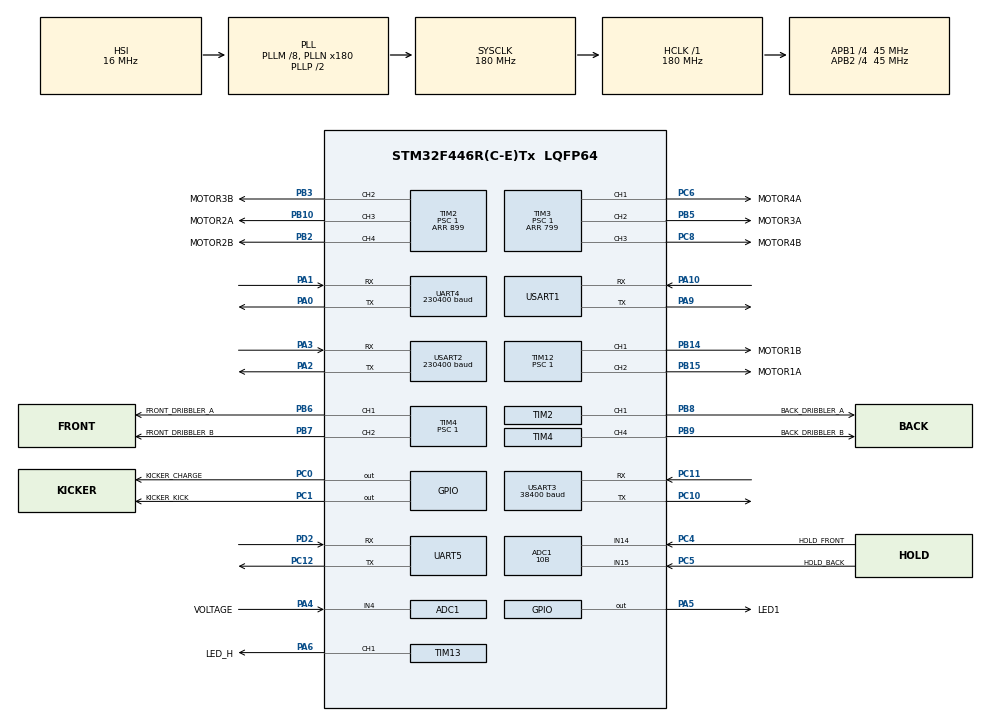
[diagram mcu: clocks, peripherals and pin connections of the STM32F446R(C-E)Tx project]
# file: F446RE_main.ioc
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ADC1.Channel-0\#ChannelRegularConversion=ADC_CHANNEL_4
ADC1.Channel-1\#ChannelRegularConversion=ADC_CHANNEL_14
ADC1.Channel-2\#ChannelRegularConversion=ADC_CHANNEL_15
ADC1.ContinuousConvMode=ENABLE
ADC1.DMAContinuousRequests=ENABLE
ADC1.NbrOfConversion=3
ADC1.NbrOfConversionFlag=1
ADC1.Rank-0\#ChannelRegularConversion=1
ADC1.Rank-1\#ChannelRegularConversion=2
ADC1.Rank-2\#ChannelRegularConversion=3
ADC1.Resolution=ADC_RESOLUTION_10B
ADC1.SamplingTime-0\#ChannelRegularConversion=ADC_SAMPLETIME_15CYCLES
ADC1.SamplingTime-1\#ChannelRegularConversion=ADC_SAMPLETIME_15CYCLES
ADC1.SamplingTime-2\#ChannelRegularConversion=ADC_SAMPLETIME_15CYCLES
ADC1.master=1
Dma.ADC1.2.Direction=DMA_PERIPH_TO_MEMORY
Dma.ADC1.2.FIFOMode=DMA_FIFOMODE_DISABLE
Dma.ADC1.2.Instance=DMA2_Stream0
Dma.ADC1.2.MemDataAlignment=DMA_MDATAALIGN_HALFWORD
Dma.ADC1.2.MemInc=DMA_MINC_ENABLE
Dma.ADC1.2.Mode=DMA_CIRCULAR
Dma.ADC1.2.PeriphDataAlignment=DMA_PDATAALIGN_HALFWORD
Dma.ADC1.2.PeriphInc=DMA_PINC_DISABLE
Dma.ADC1.2.Priority=DMA_PRIORITY_LOW
Dma.Request0=USART1_RX
Dma.Request1=USART1_TX
Dma.Request10=UART5_TX
Dma.Request2=ADC1
Dma.Request3=USART2_RX
Dma.Request4=USART2_TX
Dma.Request5=USART3_RX
Dma.Request6=USART3_TX
Dma.Request7=UART4_RX
Dma.Request8=UART4_TX
Dma.Request9=UART5_RX
Dma.UART4_RX.7.Direction=DMA_PERIPH_TO_MEMORY
Dma.UART4_RX.7.FIFOMode=DMA_FIFOMODE_DISABLE
Dma.UART4_RX.7.Instance=DMA1_Stream2
Dma.UART4_RX.7.MemDataAlignment=DMA_MDATAALIGN_BYTE
Dma.UART4_RX.7.MemInc=DMA_MINC_ENABLE
Dma.UART4_RX.7.Mode=DMA_CIRCULAR
Dma.UART4_RX.7.PeriphDataAlignment=DMA_PDATAALIGN_BYTE
Dma.UART4_RX.7.PeriphInc=DMA_PINC_DISABLE
Dma.UART4_RX.7.Priority=DMA_PRIORITY_LOW
Dma.UART4_TX.8.Direction=DMA_MEMORY_TO_PERIPH
Dma.UART4_TX.8.FIFOMode=DMA_FIFOMODE_DISABLE
Dma.UART4_TX.8.Instance=DMA1_Stream4
Dma.UART4_TX.8.MemDataAlignment=DMA_MDATAALIGN_BYTE
Dma.UART4_TX.8.MemInc=DMA_MINC_ENABLE
Dma.UART4_TX.8.Mode=DMA_CIRCULAR
Dma.UART4_TX.8.PeriphDataAlignment=DMA_PDATAALIGN_BYTE
Dma.UART4_TX.8.PeriphInc=DMA_PINC_DISABLE
Dma.UART4_TX.8.Priority=DMA_PRIORITY_LOW
Dma.UART5_RX.9.Direction=DMA_PERIPH_TO_MEMORY
Dma.UART5_RX.9.FIFOMode=DMA_FIFOMODE_DISABLE
Dma.UART5_RX.9.Instance=DMA1_Stream0
Dma.UART5_RX.9.MemDataAlignment=DMA_MDATAALIGN_BYTE
Dma.UART5_RX.9.MemInc=DMA_MINC_ENABLE
Dma.UART5_RX.9.Mode=DMA_CIRCULAR
Dma.UART5_RX.9.PeriphDataAlignment=DMA_PDATAALIGN_BYTE
Dma.UART5_RX.9.PeriphInc=DMA_PINC_DISABLE
Dma.UART5_RX.9.Priority=DMA_PRIORITY_LOW
Dma.UART5_TX.10.Direction=DMA_MEMORY_TO_PERIPH
Dma.UART5_TX.10.FIFOMode=DMA_FIFOMODE_DISABLE
Dma.UART5_TX.10.Instance=DMA1_Stream7
Dma.UART5_TX.10.MemDataAlignment=DMA_MDATAALIGN_BYTE
Dma.UART5_TX.10.MemInc=DMA_MINC_ENABLE
Dma.UART5_TX.10.Mode=DMA_CIRCULAR
Dma.UART5_TX.10.PeriphDataAlignment=DMA_PDATAALIGN_BYTE
Dma.UART5_TX.10.PeriphInc=DMA_PINC_DISABLE
Dma.UART5_TX.10.Priority=DMA_PRIORITY_LOW
Dma.USART1_RX.0.Direction=DMA_PERIPH_TO_MEMORY
Dma.USART1_RX.0.FIFOMode=DMA_FIFOMODE_DISABLE
Dma.USART1_RX.0.Instance=DMA2_Stream2
Dma.USART1_RX.0.MemDataAlignment=DMA_MDATAALIGN_BYTE
Dma.USART1_RX.0.MemInc=DMA_MINC_ENABLE
Dma.USART1_RX.0.Mode=DMA_CIRCULAR
Dma.USART1_RX.0.PeriphDataAlignment=DMA_PDATAALIGN_BYTE
Dma.USART1_RX.0.PeriphInc=DMA_PINC_DISABLE
Dma.USART1_RX.0.Priority=DMA_PRIORITY_LOW
Dma.USART1_TX.1.Direction=DMA_MEMORY_TO_PERIPH
Dma.USART1_TX.1.FIFOMode=DMA_FIFOMODE_DISABLE
Dma.USART1_TX.1.Instance=DMA2_Stream7
Dma.USART1_TX.1.MemDataAlignment=DMA_MDATAALIGN_BYTE
Dma.USART1_TX.1.MemInc=DMA_MINC_ENABLE
Dma.USART1_TX.1.Mode=DMA_CIRCULAR
Dma.USART1_TX.1.PeriphDataAlignment=DMA_PDATAALIGN_BYTE
Dma.USART1_TX.1.PeriphInc=DMA_PINC_DISABLE
Dma.USART1_TX.1.Priority=DMA_PRIORITY_LOW
Dma.USART2_RX.3.Direction=DMA_PERIPH_TO_MEMORY
Dma.USART2_RX.3.FIFOMode=DMA_FIFOMODE_DISABLE
Dma.USART2_RX.3.Instance=DMA1_Stream5
Dma.USART2_RX.3.MemDataAlignment=DMA_MDATAALIGN_BYTE
Dma.USART2_RX.3.MemInc=DMA_MINC_ENABLE
Dma.USART2_RX.3.Mode=DMA_CIRCULAR
Dma.USART2_RX.3.PeriphDataAlignment=DMA_PDATAALIGN_BYTE
Dma.USART2_RX.3.PeriphInc=DMA_PINC_DISABLE
Dma.USART2_RX.3.Priority=DMA_PRIORITY_LOW
Dma.USART2_TX.4.Direction=DMA_MEMORY_TO_PERIPH
Dma.USART2_TX.4.FIFOMode=DMA_FIFOMODE_DISABLE
Dma.USART2_TX.4.Instance=DMA1_Stream6
Dma.USART2_TX.4.MemDataAlignment=DMA_MDATAALIGN_BYTE
Dma.USART2_TX.4.MemInc=DMA_MINC_ENABLE
Dma.USART2_TX.4.Mode=DMA_CIRCULAR
Dma.USART2_TX.4.PeriphDataAlignment=DMA_PDATAALIGN_BYTE
Dma.USART2_TX.4.PeriphInc=DMA_PINC_DISABLE
Dma.USART2_TX.4.Priority=DMA_PRIORITY_LOW
Dma.USART3_RX.5.Direction=DMA_PERIPH_TO_MEMORY
Dma.USART3_RX.5.FIFOMode=DMA_FIFOMODE_DISABLE
Dma.USART3_RX.5.Instance=DMA1_Stream1
Dma.USART3_RX.5.MemDataAlignment=DMA_MDATAALIGN_BYTE
Dma.USART3_RX.5.MemInc=DMA_MINC_ENABLE
Dma.USART3_RX.5.Mode=DMA_CIRCULAR
Dma.USART3_RX.5.PeriphDataAlignment=DMA_PDATAALIGN_BYTE
Dma.USART3_RX.5.PeriphInc=DMA_PINC_DISABLE
Dma.USART3_RX.5.Priority=DMA_PRIORITY_LOW
Dma.USART3_TX.6.Direction=DMA_MEMORY_TO_PERIPH
Dma.USART3_TX.6.FIFOMode=DMA_FIFOMODE_DISABLE
Dma.USART3_TX.6.Instance=DMA1_Stream3
Dma.USART3_TX.6.MemDataAlignment=DMA_MDATAALIGN_BYTE
Dma.USART3_TX.6.MemInc=DMA_MINC_ENABLE
Dma.USART3_TX.6.Mode=DMA_CIRCULAR
Dma.USART3_TX.6.PeriphDataAlignment=DMA_PDATAALIGN_BYTE
Dma.USART3_TX.6.PeriphInc=DMA_PINC_DISABLE
Dma.USART3_TX.6.Priority=DMA_PRIORITY_LOW
Mcu.Family=STM32F4
Mcu.Name=STM32F446R(C-E)Tx
Mcu.Package=LQFP64
NVIC.DMA1_Stream0_IRQn=true\:0\:0\:false\:false\:true\:false\:true\:true
NVIC.DMA1_Stream1_IRQn=true\:0\:0\:false\:false\:true\:false\:true\:true
NVIC.DMA1_Stream2_IRQn=true\:0\:0\:false\:false\:true\:false\:true\:true
NVIC.DMA1_Stream3_IRQn=true\:0\:0\:false\:false\:true\:false\:true\:true
NVIC.DMA1_Stream4_IRQn=true\:0\:0\:false\:false\:true\:false\:true\:true
NVIC.DMA1_Stream5_IRQn=true\:0\:0\:false\:false\:true\:false\:true\:true
NVIC.DMA1_Stream6_IRQn=true\:0\:0\:false\:false\:true\:false\:true\:true
NVIC.DMA1_Stream7_IRQn=true\:0\:0\:false\:false\:true\:false\:true\:true
NVIC.DMA2_Stream0_IRQn=true\:0\:0\:false\:false\:true\:false\:true\:true
NVIC.DMA2_Stream2_IRQn=true\:0\:0\:false\:false\:true\:false\:true\:true
NVIC.DMA2_Stream7_IRQn=true\:0\:0\:false\:false\:true\:false\:true\:true
NVIC.PriorityGroup=NVIC_PRIORITYGROUP_4
NVIC.TIM1_UP_TIM10_IRQn=true\:0\:0\:false\:false\:true\:true\:true\:true
NVIC.UART4_IRQn=true\:0\:0\:false\:false\:true\:true\:true\:true
NVIC.UART5_IRQn=true\:0\:0\:false\:false\:true\:true\:true\:true
NVIC.USART1_IRQn=true\:0\:0\:false\:false\:true\:true\:true\:true
NVIC.USART2_IRQn=true\:0\:0\:false\:false\:true\:true\:true\:true
NVIC.USART3_IRQn=true\:0\:0\:false\:false\:true\:true\:true\:true
PA0-WKUP.Mode=Asynchronous
PA0-WKUP.Signal=UART4_TX
PA1.Mode=Asynchronous
PA1.Signal=UART4_RX
PA10.Mode=Asynchronous
PA10.Signal=USART1_RX
PA2.Mode=Asynchronous
PA2.Signal=USART2_TX
PA3.Mode=Asynchronous
PA3.Signal=USART2_RX
PA4.GPIO_Label=VOLTAGE
PA4.Signal=ADCx_IN4
PA5.GPIO_Label=LED1
PA5.Signal=GPIO_Output
PA6.GPIO_Label=LED_H
PA6.Signal=S_TIM13_CH1
PA9.Mode=Asynchronous
PA9.Signal=USART1_TX
PB10.GPIO_Label=MOTOR2A
PB10.Signal=S_TIM2_CH3
PB14.GPIO_Label=MOTOR1B
PB14.Signal=S_TIM12_CH1
PB15.GPIO_Label=MOTOR1A
PB15.Signal=S_TIM12_CH2
PB2.GPIO_Label=MOTOR2B
PB2.Signal=S_TIM2_CH4
PB3.GPIO_Label=MOTOR3B
PB3.Signal=S_TIM2_CH2
PB5.GPIO_Label=MOTOR3A
PB5.Signal=S_TIM3_CH2
PB6.GPIO_Label=FRONT_DRIBBLER_A
PB6.Signal=S_TIM4_CH1
PB7.GPIO_Label=FRONT_DRIBBLER_B
PB7.Signal=S_TIM4_CH2
PB8.GPIO_Label=BACK_DRIBBLER_A
PB8.Signal=S_TIM2_CH1_ETR
PB9.GPIO_Label=BACK_DRIBBLER_B
PB9.Signal=S_TIM4_CH4
PC0.GPIO_Label=KICKER_CHARGE
PC0.Signal=GPIO_Output
PC1.GPIO_Label=KICKER_KICK
PC1.Signal=GPIO_Output
PC10.Mode=Asynchronous
PC10.Signal=USART3_TX
PC11.Mode=Asynchronous
PC11.Signal=USART3_RX
PC12.Mode=Asynchronous
PC12.Signal=UART5_TX
PC4.GPIO_Label=HOLD_FRONT
PC4.Signal=ADCx_IN14
PC5.GPIO_Label=HOLD_BACK
PC5.Signal=ADCx_IN15
PC6.GPIO_Label=MOTOR4A
PC6.Signal=S_TIM3_CH1
PC8.GPIO_Label=MOTOR4B
PC8.Signal=S_TIM3_CH3
PD2.Mode=Asynchronous
PD2.Signal=UART5_RX
ProjectManager.HeapSize=0x200
ProjectManager.StackSize=0x400
ProjectManager.TargetToolchain=Makefile
RCC.AHBFreq_Value=180000000
RCC.APB1CLKDivider=RCC_HCLK_DIV4
RCC.APB1Freq_Value=45000000
RCC.APB1TimFreq_Value=90000000
RCC.APB2CLKDivider=RCC_HCLK_DIV4
RCC.APB2Freq_Value=45000000
RCC.APB2TimFreq_Value=90000000
RCC.CortexFreq_Value=180000000
RCC.HCLKFreq_Value=180000000
RCC.PLLM=8
RCC.PLLN=180
RCC.SYSCLKFreq_VALUE=180000000
RCC.SYSCLKSource=RCC_SYSCLKSOURCE_PLLCLK
RCC.USBFreq_Value=180000000
RCC.VCOOutputFreq_Value=360000000
SH.ADCx_IN14.0=ADC1_IN14,IN14
SH.ADCx_IN15.0=ADC1_IN15,IN15
SH.ADCx_IN4.0=ADC1_IN4,IN4
SH.S_TIM12_CH1.0=TIM12_CH1,PWM Generation1 CH1
SH.S_TIM12_CH2.0=TIM12_CH2,PWM Generation2 CH2
SH.S_TIM13_CH1.0=TIM13_CH1,PWM Generation1 CH1
SH.S_TIM2_CH1_ETR.0=TIM2_CH1,PWM Generation1 CH1
SH.S_TIM2_CH2.0=TIM2_CH2,PWM Generation2 CH2
SH.S_TIM2_CH3.0=TIM2_CH3,PWM Generation3 CH3
SH.S_TIM2_CH4.0=TIM2_CH4,PWM Generation4 CH4
SH.S_TIM3_CH1.0=TIM3_CH1,PWM Generation1 CH1
SH.S_TIM3_CH2.0=TIM3_CH2,PWM Generation2 CH2
SH.S_TIM3_CH3.0=TIM3_CH3,PWM Generation3 CH3
SH.S_TIM4_CH1.0=TIM4_CH1,PWM Generation1 CH1
SH.S_TIM4_CH2.0=TIM4_CH2,PWM Generation2 CH2
SH.S_TIM4_CH4.0=TIM4_CH4,PWM Generation4 CH4
TIM10.Period=9
TIM10.Prescaler=8999
TIM12.Channel-PWM\ Generation1\ CH1=TIM_CHANNEL_1
TIM12.Channel-PWM\ Generation2\ CH2=TIM_CHANNEL_2
TIM12.Period=899
TIM12.Prescaler=1
TIM13.Channel=TIM_CHANNEL_1
TIM2.Channel-PWM\ Generation1\ CH1=TIM_CHANNEL_1
TIM2.Channel-PWM\ Generation2\ CH2=TIM_CHANNEL_2
TIM2.Channel-PWM\ Generation3\ CH3=TIM_CHANNEL_3
TIM2.Channel-PWM\ Generation4\ CH4=TIM_CHANNEL_4
TIM2.Period=899
TIM2.Prescaler=1
TIM3.Channel-PWM\ Generation1\ CH1=TIM_CHANNEL_1
TIM3.Channel-PWM\ Generation2\ CH2=TIM_CHANNEL_2
TIM3.Channel-PWM\ Generation3\ CH3=TIM_CHANNEL_3
TIM3.Period=799
TIM3.Prescaler=1
TIM4.Channel-PWM\ Generation1\ CH1=TIM_CHANNEL_1
TIM4.Channel-PWM\ Generation2\ CH2=TIM_CHANNEL_2
TIM4.Channel-PWM\ Generation4\ CH4=TIM_CHANNEL_4
TIM4.Period=799
TIM4.Prescaler=1
UART4.BaudRate=230400
UART4.VirtualMode=Asynchronous
UART5.VirtualMode=Asynchronous
USART1.VirtualMode=VM_ASYNC
USART2.BaudRate=230400
USART2.VirtualMode=VM_ASYNC
USART3.BaudRate=38400
USART3.VirtualMode=VM_ASYNC
VP_TIM10_VS_ClockSourceINT.Mode=Enable_Timer
VP_TIM13_VS_ClockSourceINT.Mode=Enable_Timer
board=custom

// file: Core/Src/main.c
/* USER CODE BEGIN Header */
/**
 ******************************************************************************
 * @file           : main.c
 * @brief          : Main program body
 ******************************************************************************
 * @attention
 *
 * Copyright (c) 2025 STMicroelectronics.
 * All rights reserved.
 *
 * This software is licensed under terms that can be found in the LICENSE file
 * in the root directory of this software component.
 * If no LICENSE file comes with this software, it is provided AS-IS.
 *
 ******************************************************************************
 */
/* USER CODE END Header */
#include "main.h"
#include "adc.h"
#include "dma.h"
#include "tim.h"
#include "usart.h"
#include "gpio.h"

void SystemClock_Config(void);

/* USER CODE BEGIN 0 */
void HAL_TIM_PeriodElapsedCallback(TIM_HandleTypeDef *htim) {
      if (htim == &htim10) {
            TimInterrupt1khz();
      }
}
/* USER CODE END 0 */

int main(void)
{

  /* MCU Configuration--------------------------------------------------------*/

  /* Reset of all peripherals, Initializes the Flash interface and the Systick. */
  HAL_Init();

  /* Configure the system clock */
  SystemClock_Config();

  /* Initialize all configured peripherals */
  MX_GPIO_Init();
  MX_DMA_Init();
  MX_ADC1_Init();
  MX_TIM2_Init();
  MX_TIM3_Init();
  MX_TIM4_Init();
  MX_TIM12_Init();
  MX_TIM10_Init();
  MX_TIM13_Init();
  MX_USART1_UART_Init();
  MX_USART2_UART_Init();
  MX_USART3_UART_Init();
  MX_UART4_Init();
  MX_UART5_Init();
  /* USER CODE BEGIN 2 */
      setup();
      HAL_TIM_Base_Start_IT(&htim10);
  /* USER CODE END 2 */

  /* Infinite loop */
  /* USER CODE BEGIN WHILE */

      main_app();
      while (1) {
    /* USER CODE END WHILE */

      }
}

void SystemClock_Config(void)
{
  RCC_OscInitTypeDef RCC_OscInitStruct = {0};
  RCC_ClkInitTypeDef RCC_ClkInitStruct = {0};

  /** Configure the main internal regulator output voltage
  */
  __HAL_RCC_PWR_CLK_ENABLE();
  __HAL_PWR_VOLTAGESCALING_CONFIG(PWR_REGULATOR_VOLTAGE_SCALE1);

  /** Initializes the RCC Oscillators according to the specified parameters
  * in the RCC_OscInitTypeDef structure.
  */
  RCC_OscInitStruct.OscillatorType = RCC_OSCILLATORTYPE_HSI;
  RCC_OscInitStruct.HSIState = RCC_HSI_ON;
  RCC_OscInitStruct.HSICalibrationValue = RCC_HSICALIBRATION_DEFAULT;
  RCC_OscInitStruct.PLL.PLLState = RCC_PLL_ON;
  RCC_OscInitStruct.PLL.PLLSource = RCC_PLLSOURCE_HSI;
  RCC_OscInitStruct.PLL.PLLM = 8;
  RCC_OscInitStruct.PLL.PLLN = 180;
  RCC_OscInitStruct.PLL.PLLP = RCC_PLLP_DIV2;
  RCC_OscInitStruct.PLL.PLLQ = 2;
  RCC_OscInitStruct.PLL.PLLR = 2;
  if (HAL_RCC_OscConfig(&RCC_OscInitStruct) != HAL_OK)
  {
    Error_Handler();
  }

  /** Activate the Over-Drive mode
  */
  if (HAL_PWREx_EnableOverDrive() != HAL_OK)
  {
    Error_Handler();
  }

  /** Initializes the CPU, AHB and APB buses clocks
  */
  RCC_ClkInitStruct.ClockType = RCC_CLOCKTYPE_HCLK|RCC_CLOCKTYPE_SYSCLK
                              |RCC_CLOCKTYPE_PCLK1|RCC_CLOCKTYPE_PCLK2;
  RCC_ClkInitStruct.SYSCLKSource = RCC_SYSCLKSOURCE_PLLCLK;
  RCC_ClkInitStruct.AHBCLKDivider = RCC_SYSCLK_DIV1;
  RCC_ClkInitStruct.APB1CLKDivider = RCC_HCLK_DIV4;
  RCC_ClkInitStruct.APB2CLKDivider = RCC_HCLK_DIV4;

  if (HAL_RCC_ClockConfig(&RCC_ClkInitStruct, FLASH_LATENCY_5) != HAL_OK)
  {
    Error_Handler();
  }
}

void Error_Handler(void)
{
      __disable_irq();
      while (1) {
      }
}
